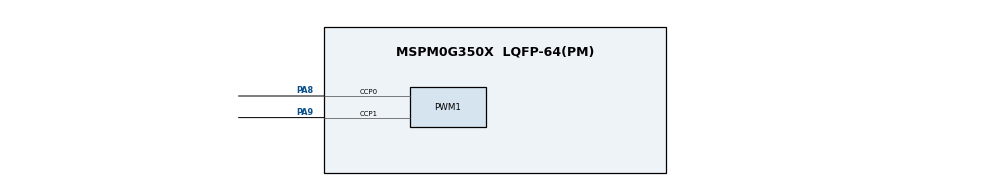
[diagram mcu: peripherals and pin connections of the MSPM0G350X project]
/**
 * @cliArgs --device "MSPM0G350X" --part "Default" --package "LQFP-64(PM)" --product "mspm0_sdk@2.05.00.05"
 * @versions {"tool":"1.24.0+4110"}
 */

/**
 * Import the modules used in this configuration.
 */
const PWM    = scripting.addModule("/ti/driverlib/PWM", {}, false);
const PWM1   = PWM.addInstance();
const SYSCTL = scripting.addModule("/ti/driverlib/SYSCTL");

/**
 * Write custom configuration values to the imported modules.
 */
const divider9       = system.clockTree["UDIV"];
divider9.divideValue = 2;

const multiplier2         = system.clockTree["PLL_QDIV"];
multiplier2.multiplyValue = 4;

const mux4       = system.clockTree["EXHFMUX"];
mux4.inputSelect = "EXHFMUX_XTAL";

const mux8       = system.clockTree["HSCLKMUX"];
mux8.inputSelect = "HSCLKMUX_SYSPLL0";

const mux12       = system.clockTree["SYSPLLMUX"];
mux12.inputSelect = "zSYSPLLMUX_HFCLK";

const pinFunction4       = system.clockTree["HFXT"];
pinFunction4.inputFreq   = 40;
pinFunction4.enable      = true;
pinFunction4.HFXTStartup = 16;

PWM1.$name                      = "PWM_0";
PWM1.clockDivider               = 8;
PWM1.timerStartTimer            = true;
PWM1.timerCount                 = 100;
PWM1.peripheral.$assign         = "TIMA0";
PWM1.peripheral.ccp0Pin.$assign = "PA8";
PWM1.peripheral.ccp1Pin.$assign = "PA9";
PWM1.PWM_CHANNEL_0.$name        = "ti_driverlib_pwm_PWMTimerCC0";
PWM1.PWM_CHANNEL_0.dutyCycle    = 50;
PWM1.PWM_CHANNEL_1.$name        = "ti_driverlib_pwm_PWMTimerCC1";
PWM1.ccp0PinConfig.$name        = "ti_driverlib_gpio_GPIOPinGeneric0";
PWM1.ccp1PinConfig.$name        = "ti_driverlib_gpio_GPIOPinGeneric1";

const Board = scripting.addModule("/ti/driverlib/Board", {}, false);

SYSCTL.forceDefaultClkConfig = true;
SYSCTL.clockTreeEn           = true;

/**
 * Pinmux solution for unlocked pins/peripherals. This ensures that minor changes to the automatic solver in a future
 * version of the tool will not impact the pinmux you originally saw.  These lines can be completely deleted in order to
 * re-solve from scratch.
 */
pinFunction4.peripheral.$suggestSolution           = "SYSCTL";
pinFunction4.peripheral.hfxInPin.$suggestSolution  = "PA5";
pinFunction4.peripheral.hfxOutPin.$suggestSolution = "PA6";
Board.peripheral.$suggestSolution                  = "DEBUGSS";
Board.peripheral.swclkPin.$suggestSolution         = "PA20";
Board.peripheral.swdioPin.$suggestSolution         = "PA19";
